# XMC4800 register map
Vendor: Infineon; File version: 1.3.0 (Reference Manual v1.3)
CPU: CM4 r2p0, little endian, MPU, FPU, 6 interrupt priority bits
Registers are 32-bit, read-write, reset 0x0 unless marked. A register's access mark holds for its fields unless they carry their own. Offsets are from the block's base; [hi:lo] are bit positions; {n}, {i} and the like mark numbered series; 'fields as' and 'values as' point back to an identical list.

## CCU40 — Capture Compare Unit 4 - Unit 0
Base 0x4000C000
Same registers: CCU41 0x40010000, CCU42 0x40014000, CCU43 0x48004000
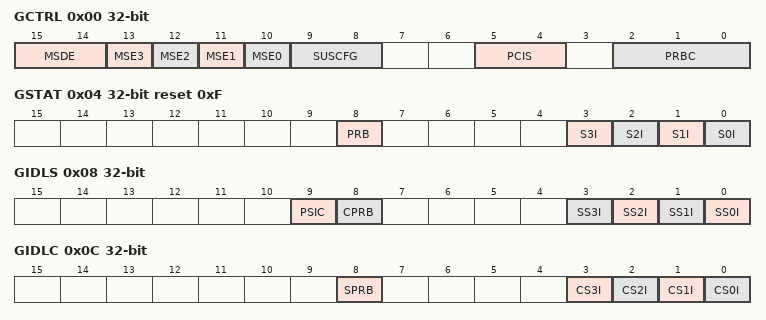
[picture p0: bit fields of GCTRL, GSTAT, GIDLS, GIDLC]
0x00 GCTRL — Global Control Register
  [15:14] MSDE — Multi Channel shadow transfer request configuration
    0=Only the shadow transfer for period and compare values is requested; 1=Shadow transfer for the compare, period and prescaler compare values is requested; 3=Shadow transfer for the compare, period, prescaler and dither compare values is requested
  [n+10] MSE{n} (n=0..3) — Slice {n} Multi Channel shadow transfer enable
    0=Shadow transfer can only be requested by SW; 1=Shadow transfer can be requested via SW and via the CCU4x.MCSS input
  [9:8] SUSCFG — Suspend Mode Configuration
    0=Suspend request ignored. The module never enters in suspend; 1=Stops all the running slices immediately. Safe stop is not applied.; 2=Stops the block immediately and clamps all the outputs to PASSIVE state. Safe stop is applied.; 3=Waits for the roll over of each slice to stop and clamp the slices outputs. Safe stop is applied.
  [5:4] PCIS — Prescaler Input Clock Selection
    0=Module clock; 1=CCU4x.ECLKA; 2=CCU4x.ECLKB; 3=CCU4x.ECLKC
  [2:0] PRBC — Prescaler Clear Configuration
    0=SW only; {v}=GSTATThe register contains the status of the prescaler and each timer slice (idle mode or running)..PRB and prescaler registers are cleared when the Run Bit of CC{v+39} is cleared (v=1..4)
0x04 GSTAT ro reset 0xF — Global Status Register
  [8] PRB — Prescaler Run Bit
    0=Prescaler is stopped; 1=Prescaler is running
  [n] S{n}I (n=0..3) — CC{n+40} IDLE status
    0=Running; 1=Idle
0x08 GIDLS wo — Global Idle Set
  [9] PSIC — Prescaler clear
  [8] CPRB — Prescaler Run Bit Clear
  [n] SS{n}I (n=0..3) — CC{n+40} IDLE mode set
0x0C GIDLC wo — Global Idle Clear
  [8] SPRB — Prescaler Run Bit Set
  [n] CS{n}I (n=0..3) — CC{n+40} IDLE mode clear
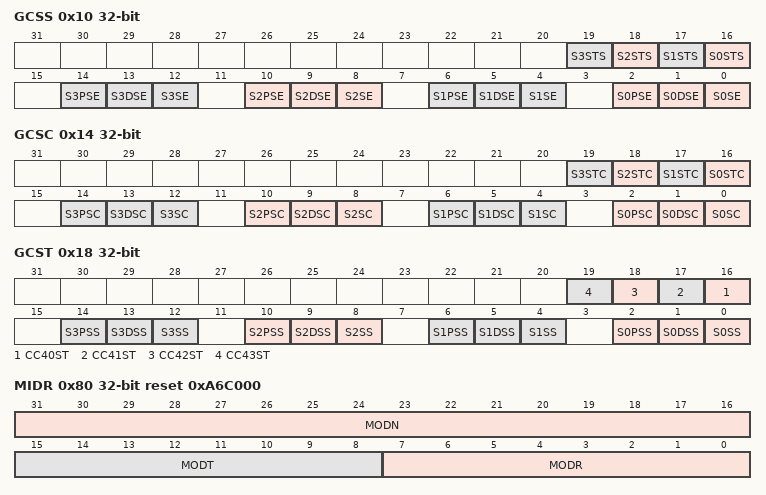
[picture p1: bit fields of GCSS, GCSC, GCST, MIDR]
0x10 GCSS wo — Global Channel Set
  [n+16] S{n}STS (n=0..3) — Slice {n} status bit set
  [4n+2] S{n}PSE (n=0..3) — Slice {n} Prescaler shadow transfer set enable
  [4n+1] S{n}DSE (n=0..3) — Slice {n} Dither shadow transfer set enable
  [4n] S{n}SE (n=0..3) — Slice {n} shadow transfer set enable
0x14 GCSC wo — Global Channel Clear
  [n+16] S{n}STC (n=0..3) — Slice {n} status bit clear
  [4n+2] S{n}PSC (n=0..3) — Slice {n} Prescaler shadow transfer clear
  [4n+1] S{n}DSC (n=0..3) — Slice {n} Dither shadow transfer clear
  [4n] S{n}SC (n=0..3) — Slice {n} shadow transfer clear
0x18 GCST ro — Global Channel Status
  [n-24] CC{n}ST (n=40..43) — Slice {n-40} status bit
  [4n+2] S{n}PSS (n=0..3) — Slice {n} Prescaler shadow transfer status
    0=Prescaler shadow transfer has not been requested; 1=Prescaler shadow transfer has been requested
  [4n+1] S{n}DSS (n=0..3) — Slice {n} Dither shadow transfer status
    0=Dither shadow transfer has not been requested; 1=Dither shadow transfer has been requested
  [4n] S{n}SS (n=0..3) — Slice {n} shadow transfer status
    0=Shadow transfer has not been requested; 1=Shadow transfer has been requested
0x80 MIDR ro reset 0xA6C000 (reset mask 0xFFFFFF00) — Module Identification
  [31:16] MODN — Module Number
  [15:8] MODT — Module Type
  [7:0] MODR — Module Revision

## PORT4
Base 0x48028400
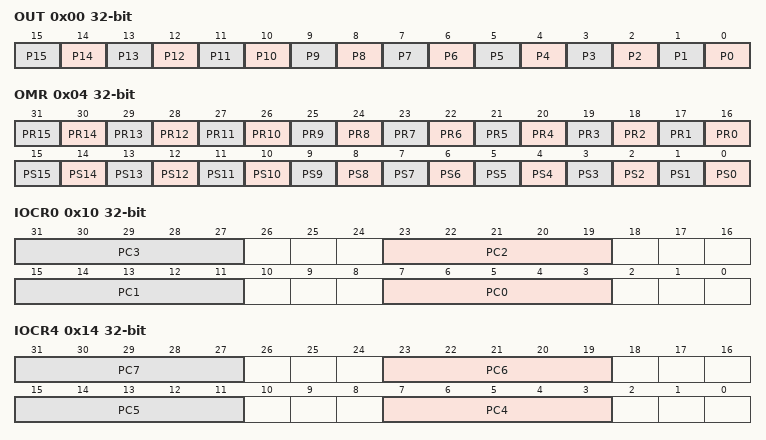
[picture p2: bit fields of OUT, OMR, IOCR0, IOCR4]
0x00 OUT — Port 4 Output Register
  [all] fields
    0=The output level of Pn.x is 0; 1=The output level of Pn.x is 1
  [n] P{n} (n=0..15) — Port n Output Bit {n}
0x04 OMR wo — Port 4 Output Modification Register
  [n+16] PR{n} (n=0..15) — Port n Reset Bit {n}
  [n] PS{n} (n=0..15) — Port n Set Bit {n}
0x10 IOCR0 — Port 4 Input/Output Control Register 0
  [all] fields
    0=Input - No internal pull device active; 1=Input - Internal pull-down device active; 2=Input - Internal pull-up device active; 3=Input - No internal pull device, Pn_OUTx = input value; 4=Input inverted - No internal pull device active; 5=Input inverted - Internal pull-down device active; 6=Input inverted - Internal pull-up device active; 7=Input inverted - No internal pull device, Pn_OUTx = input value; 16=Output Push-Pull - General-purpose output; {v}=Output Push-Pull - Alternate output function {v-16} (v=17..20); 24=Output Open Drain - General-purpose output; {v}=Output Open Drain - Alternate output function {v-24} (v=25..28)
  [8n+7:8n+3] PC{n} (n=0..3) — Port Control for Port n Pin 0 to 3
0x14 IOCR4 — Port 4 Input/Output Control Register 4
  [all] fields
    values as the fields of IOCR0
  [8n-25:8n-29] PC{n} (n=4..7) — Port Control for Port n Pin 4 to 7
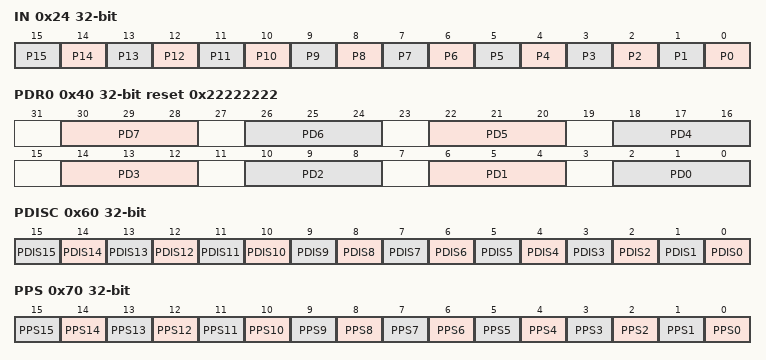
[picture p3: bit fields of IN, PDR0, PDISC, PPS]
0x24 IN ro (reset mask 0xFFFF0000) — Port 4 Input Register
  [all] fields
    0=The input level of Pn.x is 0; 1=The input level of Pn.x is 1
  [n] P{n} (n=0..15) — Port n Input Bit {n}
0x40 PDR0 reset 0x22222222 — Port 4 Pad Driver Mode 0 Register
  [30:28] PD7 — Pad Driver Mode for Pn.7
    2=sd_soe (A1+ strong driver, soft edge); 3=sd_sle (A1+ strong driver, slow edge); 4=md (A1+ medium driver); 7=wd (A1+ weak driver); 0=sd_soe_alt (A1+ strong driver, soft edge (alternate value)); 1=sd_sle_alt (A1+ strong driver, slow edge (alternate value)); 6=md_alt (A1+ medium driver (alternate value)); 5=wd_alt (A1+ weak driver (alternate value))
  [26:24] PD6 — Pad Driver Mode for Pn.6
    values as PD7
  [22:20] PD5 — Pad Driver Mode for Pn.5
    values as PD7
  [18:16] PD4 — Pad Driver Mode for Pn.4
    values as PD7
  [14:12] PD3 — Pad Driver Mode for Pn.3
    values as PD7
  [10:8] PD2 — Pad Driver Mode for Pn.2
    values as PD7
  [6:4] PD1 — Pad Driver Mode for Pn.1
    0=sd_she (A2 strong driver, sharp edge); 1=sd_mee (A2 strong driver, medium edge); 2=sd_soe (A2 strong driver, soft edge); 4=md (A2 medium driver); 7=wd (A2 weak driver)
  [2:0] PD0 — Pad Driver Mode for Pn.0
    values as PD1
0x60 PDISC ro (reset mask 0xFFFF0000) — Port 4 Pin Function Decision Control Register
  [all] fields
    0=Pad Pn.x is enabled; 1=Pad Pn.x is disabled
  [n] PDIS{n} (n=0..15) — Pad Disable for Port n Pin {n}
0x70 PPS — Port 4 Pin Power Save Register
  [all] fields
    0=Pin Power Save of Pn.x is disabled; 1=Pin Power Save of Pn.x is enabled
  [n] PPS{n} (n=0..15) — Port n Pin Power Save Bit {n}
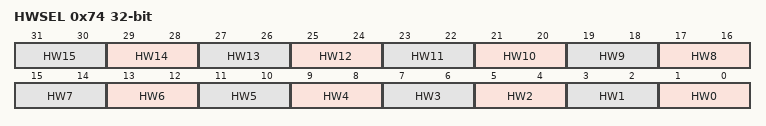
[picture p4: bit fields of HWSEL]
0x74 HWSEL — Port 4 Pin Hardware Select Register
  [all] fields
    0=Software control only; 1=HW0 control path can override the software configuration; 2=HW1 control path can override the software configuration
  [2n+1:2n] HW{n} (n=0..15) — Port n Pin Hardware Select Bit {n}
